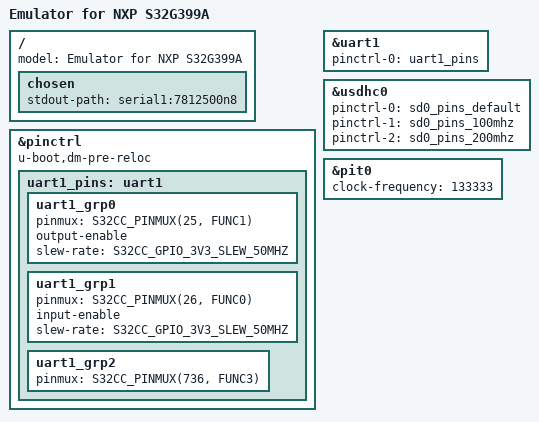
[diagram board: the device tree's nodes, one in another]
// SPDX-License-Identifier: (GPL-2.0+ OR BSD-3-Clause)
/*
 * Copyright 2021-2023 NXP
 */

/dts-v1/;
#include "s32g.dtsi"
#include "s32g3.dtsi"

/delete-node/ &mem2;
/ {
	model = "Emulator for NXP S32G399A";

	chosen {
		stdout-path = "serial1:7812500n8";
	};
};

&pinctrl {
	u-boot,dm-pre-reloc;

	uart1_pins: uart1 {
		uart1_grp0 {
			pinmux = <S32CC_PINMUX(25, FUNC1)>;
			output-enable;
			slew-rate = <S32CC_GPIO_3V3_SLEW_50MHZ>;
		};

		uart1_grp1 {
			pinmux = <S32CC_PINMUX(26, FUNC0)>;
			input-enable;
			slew-rate = <S32CC_GPIO_3V3_SLEW_50MHZ>;
		};

		uart1_grp2 {
			pinmux = <S32CC_PINMUX(736, FUNC3)>;
		};
	};
};

&uart1{
	pinctrl-0 = <&uart1_pins>;
	pinctrl-names = "default";
	status = "okay";
};

&usdhc0 {
	pinctrl-names = "default", "state_100mhz", "state_200mhz";
	pinctrl-0 = <&sd0_pins_default>;
	pinctrl-1 = <&sd0_pins_100mhz>;
	pinctrl-2 = <&sd0_pins_200mhz>;
	status = "okay";
};

&pit0 {
	/delete-property/ clocks;
	/delete-property/ clock-names;
	/**
	 * Artificially reduce the frequency to 1/10 of the real rate
	 * to increase responsiveness
	 */
	clock-frequency = <133333>;
};
